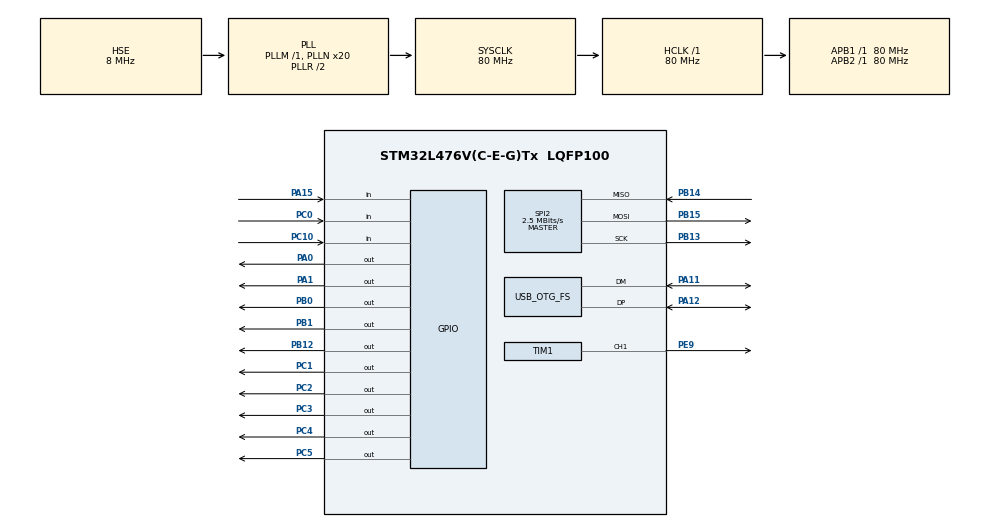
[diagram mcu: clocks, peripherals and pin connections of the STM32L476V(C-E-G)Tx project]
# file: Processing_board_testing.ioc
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Mcu.Family=STM32L4
Mcu.Name=STM32L476V(C-E-G)Tx
Mcu.Package=LQFP100
NVIC.OTG_FS_IRQn=true\:0\:0\:false\:false\:true\:false\:true\:true
NVIC.PriorityGroup=NVIC_PRIORITYGROUP_4
PA0.Signal=GPIO_Output
PA1.Signal=GPIO_Output
PA11.Mode=Device_Only
PA11.Signal=USB_OTG_FS_DM
PA12.Mode=Device_Only
PA12.Signal=USB_OTG_FS_DP
PA13\ (JTMS-SWDIO).Mode=Serial_Wire
PA13\ (JTMS-SWDIO).Signal=SYS_JTMS-SWDIO
PA14\ (JTCK-SWCLK).Mode=Serial_Wire
PA14\ (JTCK-SWCLK).Signal=SYS_JTCK-SWCLK
PA15\ (JTDI).Signal=GPIO_Input
PB0.Signal=GPIO_Output
PB1.Signal=GPIO_Output
PB12.PinState=GPIO_PIN_SET
PB12.Signal=GPIO_Output
PB13.Mode=Full_Duplex_Master
PB13.Signal=SPI2_SCK
PB14.GPIO_PuPd=GPIO_PULLDOWN
PB14.Mode=Full_Duplex_Master
PB14.Signal=SPI2_MISO
PB15.Mode=Full_Duplex_Master
PB15.Signal=SPI2_MOSI
PC0.Signal=GPIO_Input
PC1.Signal=GPIO_Output
PC10.Signal=GPIO_Input
PC2.Signal=GPIO_Output
PC3.Signal=GPIO_Output
PC4.Signal=GPIO_Output
PC5.Signal=GPIO_Output
PE9.Signal=S_TIM1_CH1
PH0-OSC_IN\ (PH0).Mode=HSE-External-Oscillator
PH0-OSC_IN\ (PH0).Signal=RCC_OSC_IN
PH1-OSC_OUT\ (PH1).Mode=HSE-External-Oscillator
PH1-OSC_OUT\ (PH1).Signal=RCC_OSC_OUT
ProjectManager.HeapSize=0x200
ProjectManager.StackSize=0x400
ProjectManager.TargetToolchain=STM32CubeIDE
RCC.ADCFreq_Value=48000000
RCC.AHBFreq_Value=80000000
RCC.APB1Freq_Value=80000000
RCC.APB1TimFreq_Value=80000000
RCC.APB2Freq_Value=80000000
RCC.APB2TimFreq_Value=80000000
RCC.CortexFreq_Value=80000000
RCC.HCLKFreq_Value=80000000
RCC.HSE_VALUE=8000000
RCC.HSI_VALUE=16000000
RCC.LSE_VALUE=32768
RCC.MSI_VALUE=4000000
RCC.PLLN=20
RCC.PLLSAI1N=12
RCC.PLLSourceVirtual=RCC_PLLSOURCE_HSE
RCC.SYSCLKFreq_VALUE=80000000
RCC.SYSCLKSource=RCC_SYSCLKSOURCE_PLLCLK
RCC.USBFreq_Value=48000000
RCC.VCOOutputFreq_Value=160000000
SH.S_TIM1_CH1.0=TIM1_CH1,PWM Generation1 CH1
SPI2.BaudRatePrescaler=SPI_BAUDRATEPRESCALER_32
SPI2.CalculateBaudRate=2.5 MBits/s
SPI2.DataSize=SPI_DATASIZE_8BIT
SPI2.Direction=SPI_DIRECTION_2LINES
SPI2.Mode=SPI_MODE_MASTER
SPI2.VirtualType=VM_MASTER
TIM1.AutoReloadPreload=TIM_AUTORELOAD_PRELOAD_ENABLE
TIM1.Channel-PWM\ Generation1\ CH1=TIM_CHANNEL_1
TIM1.OCMode_PWM-PWM\ Generation1\ CH1=TIM_OCMODE_PWM2
TIM1.Period=15999
TIM1.Pulse-PWM\ Generation1\ CH1=15920
USB_DEVICE.CLASS_NAME_FS=CDC
USB_DEVICE.VirtualMode=Cdc
USB_DEVICE.VirtualModeFS=Cdc_FS
USB_OTG_FS.VirtualMode=Device_Only
VP_TIM1_VS_ClockSourceINT.Mode=Internal
VP_USB_DEVICE_VS_USB_DEVICE_CDC_FS.Mode=CDC_FS
board=custom

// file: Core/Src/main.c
/* USER CODE BEGIN Header */
/**
  ******************************************************************************
  * @file           : main.c
  * @brief          : Main program body
  ******************************************************************************
  * @attention
  *
  * Copyright (c) 2026 STMicroelectronics.
  * All rights reserved.
  *
  * This software is licensed under terms that can be found in the LICENSE file
  * in the root directory of this software component.
  * If no LICENSE file comes with this software, it is provided AS-IS.
  *
  ******************************************************************************
  */
/* USER CODE END Header */
#include "main.h"
#include "usb_device.h"

/* USER CODE BEGIN Includes */
#include "led_test.h"
#include "usb_cmd.h"
#include "dds_cmd.h"
/* USER CODE END Includes */

SPI_HandleTypeDef hspi2;

TIM_HandleTypeDef htim1;

void SystemClock_Config(void);
static void MX_GPIO_Init(void);
static void MX_SPI2_Init(void);
static void MX_TIM1_Init(void);

int main(void)
{

  /* MCU Configuration--------------------------------------------------------*/

  /* Reset of all peripherals, Initializes the Flash interface and the Systick. */
  HAL_Init();

  /* Configure the system clock */
  SystemClock_Config();

  /* Initialize all configured peripherals */
  MX_GPIO_Init();
  MX_USB_DEVICE_Init();
  MX_SPI2_Init();
  MX_TIM1_Init();
  /* USER CODE BEGIN 2 */
  LedTest_Init();
  DdsCmd_Init();

  LedTest_Enable(1);
  LedTest_Set(0x1);               /* red on */
  HAL_Delay(300);
  LedTest_Set(0x0);               /* red off */
  /* USER CODE END 2 */

  /* Infinite loop */
  while (1)
  {

    /* USER CODE BEGIN 3 */
	  UsbCmd_Poll();
  }
  /* USER CODE END 3 */
}

void SystemClock_Config(void)
{
  RCC_OscInitTypeDef RCC_OscInitStruct = {0};
  RCC_ClkInitTypeDef RCC_ClkInitStruct = {0};

  /** Configure the main internal regulator output voltage
  */
  if (HAL_PWREx_ControlVoltageScaling(PWR_REGULATOR_VOLTAGE_SCALE1) != HAL_OK)
  {
    Error_Handler();
  }

  /** Initializes the RCC Oscillators according to the specified parameters
  * in the RCC_OscInitTypeDef structure.
  */
  RCC_OscInitStruct.OscillatorType = RCC_OSCILLATORTYPE_HSE;
  RCC_OscInitStruct.HSEState = RCC_HSE_ON;
  RCC_OscInitStruct.PLL.PLLState = RCC_PLL_ON;
  RCC_OscInitStruct.PLL.PLLSource = RCC_PLLSOURCE_HSE;
  RCC_OscInitStruct.PLL.PLLM = 1;
  RCC_OscInitStruct.PLL.PLLN = 20;
  RCC_OscInitStruct.PLL.PLLP = RCC_PLLP_DIV7;
  RCC_OscInitStruct.PLL.PLLQ = RCC_PLLQ_DIV2;
  RCC_OscInitStruct.PLL.PLLR = RCC_PLLR_DIV2;
  if (HAL_RCC_OscConfig(&RCC_OscInitStruct) != HAL_OK)
  {
    Error_Handler();
  }

  /** Initializes the CPU, AHB and APB buses clocks
  */
  RCC_ClkInitStruct.ClockType = RCC_CLOCKTYPE_HCLK|RCC_CLOCKTYPE_SYSCLK
                              |RCC_CLOCKTYPE_PCLK1|RCC_CLOCKTYPE_PCLK2;
  RCC_ClkInitStruct.SYSCLKSource = RCC_SYSCLKSOURCE_PLLCLK;
  RCC_ClkInitStruct.AHBCLKDivider = RCC_SYSCLK_DIV1;
  RCC_ClkInitStruct.APB1CLKDivider = RCC_HCLK_DIV1;
  RCC_ClkInitStruct.APB2CLKDivider = RCC_HCLK_DIV1;

  if (HAL_RCC_ClockConfig(&RCC_ClkInitStruct, FLASH_LATENCY_4) != HAL_OK)
  {
    Error_Handler();
  }
}

static void MX_SPI2_Init(void)
{

  /* SPI2 parameter configuration*/
  hspi2.Instance = SPI2;
  hspi2.Init.Mode = SPI_MODE_MASTER;
  hspi2.Init.Direction = SPI_DIRECTION_2LINES;
  hspi2.Init.DataSize = SPI_DATASIZE_8BIT;
  hspi2.Init.CLKPolarity = SPI_POLARITY_LOW;
  hspi2.Init.CLKPhase = SPI_PHASE_1EDGE;
  hspi2.Init.NSS = SPI_NSS_SOFT;
  hspi2.Init.BaudRatePrescaler = SPI_BAUDRATEPRESCALER_32;
  hspi2.Init.FirstBit = SPI_FIRSTBIT_MSB;
  hspi2.Init.TIMode = SPI_TIMODE_DISABLE;
  hspi2.Init.CRCCalculation = SPI_CRCCALCULATION_DISABLE;
  hspi2.Init.CRCPolynomial = 7;
  hspi2.Init.CRCLength = SPI_CRC_LENGTH_DATASIZE;
  hspi2.Init.NSSPMode = SPI_NSS_PULSE_ENABLE;
  if (HAL_SPI_Init(&hspi2) != HAL_OK)
  {
    Error_Handler();
  }

}

static void MX_TIM1_Init(void)
{

  TIM_ClockConfigTypeDef sClockSourceConfig = {0};
  TIM_MasterConfigTypeDef sMasterConfig = {0};
  TIM_OC_InitTypeDef sConfigOC = {0};
  TIM_BreakDeadTimeConfigTypeDef sBreakDeadTimeConfig = {0};

  htim1.Instance = TIM1;
  htim1.Init.Prescaler = 0;
  htim1.Init.CounterMode = TIM_COUNTERMODE_UP;
  htim1.Init.Period = 15999;
  htim1.Init.ClockDivision = TIM_CLOCKDIVISION_DIV1;
  htim1.Init.RepetitionCounter = 0;
  htim1.Init.AutoReloadPreload = TIM_AUTORELOAD_PRELOAD_ENABLE;
  if (HAL_TIM_Base_Init(&htim1) != HAL_OK)
  {
    Error_Handler();
  }
  sClockSourceConfig.ClockSource = TIM_CLOCKSOURCE_INTERNAL;
  if (HAL_TIM_ConfigClockSource(&htim1, &sClockSourceConfig) != HAL_OK)
  {
    Error_Handler();
  }
  if (HAL_TIM_PWM_Init(&htim1) != HAL_OK)
  {
    Error_Handler();
  }
  sMasterConfig.MasterOutputTrigger = TIM_TRGO_RESET;
  sMasterConfig.MasterOutputTrigger2 = TIM_TRGO2_RESET;
  sMasterConfig.MasterSlaveMode = TIM_MASTERSLAVEMODE_DISABLE;
  if (HAL_TIMEx_MasterConfigSynchronization(&htim1, &sMasterConfig) != HAL_OK)
  {
    Error_Handler();
  }
  sConfigOC.OCMode = TIM_OCMODE_PWM2;
  sConfigOC.Pulse = 15920;
  sConfigOC.OCPolarity = TIM_OCPOLARITY_HIGH;
  sConfigOC.OCNPolarity = TIM_OCNPOLARITY_HIGH;
  sConfigOC.OCFastMode = TIM_OCFAST_DISABLE;
  sConfigOC.OCIdleState = TIM_OCIDLESTATE_RESET;
  sConfigOC.OCNIdleState = TIM_OCNIDLESTATE_RESET;
  if (HAL_TIM_PWM_ConfigChannel(&htim1, &sConfigOC, TIM_CHANNEL_1) != HAL_OK)
  {
    Error_Handler();
  }
  sBreakDeadTimeConfig.OffStateRunMode = TIM_OSSR_DISABLE;
  sBreakDeadTimeConfig.OffStateIDLEMode = TIM_OSSI_DISABLE;
  sBreakDeadTimeConfig.LockLevel = TIM_LOCKLEVEL_OFF;
  sBreakDeadTimeConfig.DeadTime = 0;
  sBreakDeadTimeConfig.BreakState = TIM_BREAK_DISABLE;
  sBreakDeadTimeConfig.BreakPolarity = TIM_BREAKPOLARITY_HIGH;
  sBreakDeadTimeConfig.BreakFilter = 0;
  sBreakDeadTimeConfig.Break2State = TIM_BREAK2_DISABLE;
  sBreakDeadTimeConfig.Break2Polarity = TIM_BREAK2POLARITY_HIGH;
  sBreakDeadTimeConfig.Break2Filter = 0;
  sBreakDeadTimeConfig.AutomaticOutput = TIM_AUTOMATICOUTPUT_DISABLE;
  if (HAL_TIMEx_ConfigBreakDeadTime(&htim1, &sBreakDeadTimeConfig) != HAL_OK)
  {
    Error_Handler();
  }
  HAL_TIM_MspPostInit(&htim1);

}

static void MX_GPIO_Init(void)
{
  GPIO_InitTypeDef GPIO_InitStruct = {0};

  /* GPIO Ports Clock Enable */
  __HAL_RCC_GPIOH_CLK_ENABLE();
  __HAL_RCC_GPIOC_CLK_ENABLE();
  __HAL_RCC_GPIOA_CLK_ENABLE();
  __HAL_RCC_GPIOB_CLK_ENABLE();
  __HAL_RCC_GPIOE_CLK_ENABLE();

  /*Configure GPIO pin Output Level */
  HAL_GPIO_WritePin(GPIOC, GPIO_PIN_1|GPIO_PIN_2|GPIO_PIN_3|GPIO_PIN_4
                          |GPIO_PIN_5, GPIO_PIN_RESET);

  /*Configure GPIO pin Output Level */
  HAL_GPIO_WritePin(GPIOA, GPIO_PIN_0|GPIO_PIN_1, GPIO_PIN_RESET);

  /*Configure GPIO pin Output Level */
  HAL_GPIO_WritePin(GPIOB, GPIO_PIN_0|GPIO_PIN_1, GPIO_PIN_RESET);

  /*Configure GPIO pin Output Level */
  HAL_GPIO_WritePin(GPIOB, GPIO_PIN_12, GPIO_PIN_SET);

  /*Configure GPIO pins : PC0 PC10 */
  GPIO_InitStruct.Pin = GPIO_PIN_0|GPIO_PIN_10;
  GPIO_InitStruct.Mode = GPIO_MODE_INPUT;
  GPIO_InitStruct.Pull = GPIO_NOPULL;
  HAL_GPIO_Init(GPIOC, &GPIO_InitStruct);

  /*Configure GPIO pins : PC1 PC2 PC3 PC4
                           PC5 */
  GPIO_InitStruct.Pin = GPIO_PIN_1|GPIO_PIN_2|GPIO_PIN_3|GPIO_PIN_4
                          |GPIO_PIN_5;
  GPIO_InitStruct.Mode = GPIO_MODE_OUTPUT_PP;
  GPIO_InitStruct.Pull = GPIO_NOPULL;
  GPIO_InitStruct.Speed = GPIO_SPEED_FREQ_LOW;
  HAL_GPIO_Init(GPIOC, &GPIO_InitStruct);

  /*Configure GPIO pins : PA0 PA1 */
  GPIO_InitStruct.Pin = GPIO_PIN_0|GPIO_PIN_1;
  GPIO_InitStruct.Mode = GPIO_MODE_OUTPUT_PP;
  GPIO_InitStruct.Pull = GPIO_NOPULL;
  GPIO_InitStruct.Speed = GPIO_SPEED_FREQ_LOW;
  HAL_GPIO_Init(GPIOA, &GPIO_InitStruct);

  /*Configure GPIO pins : PB0 PB1 PB12 */
  GPIO_InitStruct.Pin = GPIO_PIN_0|GPIO_PIN_1|GPIO_PIN_12;
  GPIO_InitStruct.Mode = GPIO_MODE_OUTPUT_PP;
  GPIO_InitStruct.Pull = GPIO_NOPULL;
  GPIO_InitStruct.Speed = GPIO_SPEED_FREQ_LOW;
  HAL_GPIO_Init(GPIOB, &GPIO_InitStruct);

  /*Configure GPIO pin : PA15 */
  GPIO_InitStruct.Pin = GPIO_PIN_15;
  GPIO_InitStruct.Mode = GPIO_MODE_INPUT;
  GPIO_InitStruct.Pull = GPIO_NOPULL;
  HAL_GPIO_Init(GPIOA, &GPIO_InitStruct);

}

void Error_Handler(void)
{
  __disable_irq();
  while (1)
  {
  }
}
